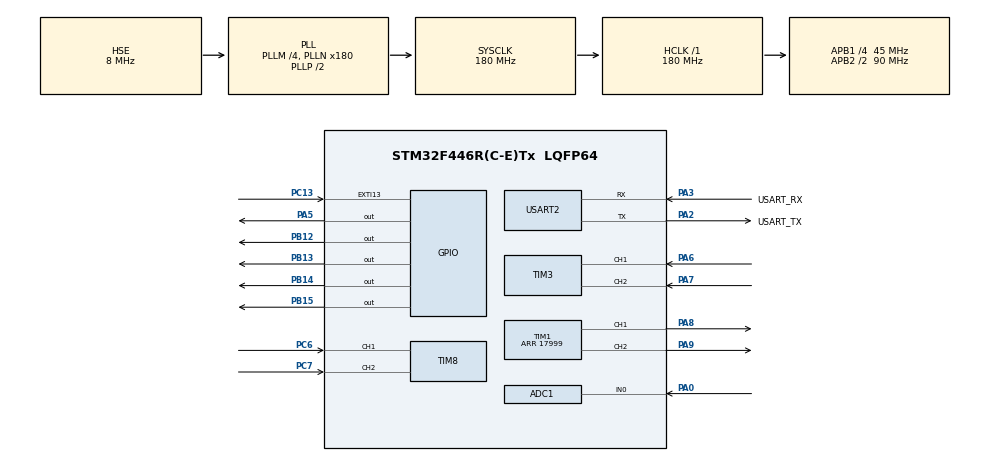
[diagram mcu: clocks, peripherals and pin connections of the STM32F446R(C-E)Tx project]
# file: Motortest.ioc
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ADC1.Channel-0\#ChannelRegularConversion=ADC_CHANNEL_0
ADC1.NbrOfConversionFlag=1
ADC1.Rank-0\#ChannelRegularConversion=1
ADC1.SamplingTime-0\#ChannelRegularConversion=ADC_SAMPLETIME_480CYCLES
ADC1.master=1
Mcu.Family=STM32F4
Mcu.Name=STM32F446R(C-E)Tx
Mcu.Package=LQFP64
NUCLEO-F446RE.BUTTON=1
NUCLEO-F446RE.LD1=true
NVIC.EXTI15_10_IRQn=true\:0\:0\:false\:false\:true\:false\:true\:true
NVIC.PriorityGroup=NVIC_PRIORITYGROUP_0
NVIC.TIM6_DAC_IRQn=true\:0\:0\:false\:false\:true\:true\:true\:true
NVIC.USART2_IRQn=true\:0\:0\:false\:false\:true\:true\:true\:true
PA0-WKUP.Signal=ADCx_IN0
PA13.GPIO_Label=TMS
PA13.Mode=Serial_Wire
PA13.Signal=SYS_JTMS-SWDIO
PA14.GPIO_Label=TCK
PA14.Mode=Serial_Wire
PA14.Signal=SYS_JTCK-SWCLK
PA2.GPIO_Label=USART_TX
PA2.Mode=Asynchronous
PA2.Signal=USART2_TX
PA3.GPIO_Label=USART_RX
PA3.Mode=Asynchronous
PA3.Signal=USART2_RX
PA5.Signal=GPIO_Output
PA6.Signal=S_TIM3_CH1
PA7.Signal=S_TIM3_CH2
PA8.Signal=S_TIM1_CH1
PA9.Signal=S_TIM1_CH2
PB12.GPIO_PuPd=GPIO_PULLDOWN
PB12.Signal=GPIO_Output
PB13.GPIO_PuPd=GPIO_PULLDOWN
PB13.Signal=GPIO_Output
PB14.GPIO_PuPd=GPIO_PULLDOWN
PB14.Signal=GPIO_Output
PB15.GPIO_PuPd=GPIO_PULLDOWN
PB15.Signal=GPIO_Output
PB3.GPIO_Label=SWO
PB3.Signal=SYS_JTDO-SWO
PC13.Signal=GPXTI13
PC14-OSC32_IN.Signal=RCC_OSC32_IN
PC15-OSC32_OUT.Signal=RCC_OSC32_OUT
PC6.Signal=S_TIM8_CH1
PC7.Signal=S_TIM8_CH2
PH0-OSC_IN.Mode=HSE-External-Clock-Source
PH0-OSC_IN.Signal=RCC_OSC_IN
PH1-OSC_OUT.Mode=HSE-External-Clock-Source
PH1-OSC_OUT.Signal=RCC_OSC_OUT
ProjectManager.HeapSize=0x200
ProjectManager.StackSize=0x400
ProjectManager.TargetToolchain=STM32CubeIDE
RCC.AHBFreq_Value=180000000
RCC.APB1CLKDivider=RCC_HCLK_DIV4
RCC.APB1Freq_Value=45000000
RCC.APB1TimFreq_Value=90000000
RCC.APB2CLKDivider=RCC_HCLK_DIV2
RCC.APB2Freq_Value=90000000
RCC.APB2TimFreq_Value=180000000
RCC.CortexFreq_Value=180000000
RCC.FLatency-AdvancedSettings=FLASH_LATENCY_5
RCC.HCLKFreq_Value=180000000
RCC.HSE_VALUE=8000000
RCC.HSI_VALUE=16000000
RCC.PLLM=4
RCC.PLLN=180
RCC.PLLSourceVirtual=RCC_PLLSOURCE_HSE
RCC.SYSCLKFreq_VALUE=180000000
RCC.SYSCLKSource=RCC_SYSCLKSOURCE_PLLCLK
RCC.USBFreq_Value=180000000
RCC.VCOOutputFreq_Value=360000000
SH.ADCx_IN0.0=ADC1_IN0,IN0
SH.S_TIM1_CH1.0=TIM1_CH1,PWM Generation1 CH1
SH.S_TIM1_CH2.0=TIM1_CH2,PWM Generation2 CH2
SH.S_TIM3_CH1.0=TIM3_CH1,Encoder_Interface
SH.S_TIM3_CH2.0=TIM3_CH2,Encoder_Interface
SH.S_TIM8_CH1.0=TIM8_CH1,Encoder_Interface
SH.S_TIM8_CH2.0=TIM8_CH2,Encoder_Interface
TIM1.Channel-PWM\ Generation1\ CH1=TIM_CHANNEL_1
TIM1.Channel-PWM\ Generation2\ CH2=TIM_CHANNEL_2
TIM1.Period=17999
TIM2.Prescaler=89
TIM3.EncoderMode=TIM_ENCODERMODE_TI12
TIM3.IC1Filter=15
TIM3.IC2Filter=15
TIM6.Period=9
TIM6.Prescaler=8999
TIM8.ClockDivision=TIM_CLOCKDIVISION_DIV2
TIM8.EncoderMode=TIM_ENCODERMODE_TI12
TIM8.IC1Filter=15
TIM8.IC2Filter=15
USART2.VirtualMode=VM_ASYNC
VP_NUCLEO-F446RE_VS_BSP_COMMON.Mode=COMMON
VP_TIM2_VS_ClockSourceINT.Mode=Internal
VP_TIM6_VS_ClockSourceINT.Mode=Enable_Timer
board=NUCLEO-F446RE

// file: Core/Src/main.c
/* USER CODE BEGIN Header */
/**
  ******************************************************************************
  * @file           : main.c
  * @brief          : Main program body
  ******************************************************************************
  * @attention
  *
  * Copyright (c) 2026 STMicroelectronics.
  * All rights reserved.
  *
  * This software is licensed under terms that can be found in the LICENSE file
  * in the root directory of this software component.
  * If no LICENSE file comes with this software, it is provided AS-IS.
  *
  ******************************************************************************
  */
/* USER CODE END Header */
#include "main.h"

/* USER CODE BEGIN Includes */
#include "bench.h"

/* USER CODE END Includes */

ADC_HandleTypeDef hadc1;

TIM_HandleTypeDef htim1;
TIM_HandleTypeDef htim2;
TIM_HandleTypeDef htim3;
TIM_HandleTypeDef htim6;
TIM_HandleTypeDef htim8;

UART_HandleTypeDef huart2;

void SystemClock_Config(void);
static void MX_GPIO_Init(void);
static void MX_ADC1_Init(void);
static void MX_TIM1_Init(void);
static void MX_TIM2_Init(void);
static void MX_TIM3_Init(void);
static void MX_TIM6_Init(void);
static void MX_TIM8_Init(void);
static void MX_USART2_UART_Init(void);

int main(void)
{

  /* MCU Configuration--------------------------------------------------------*/

  /* Reset of all peripherals, Initializes the Flash interface and the Systick. */
  HAL_Init();

  /* Configure the system clock */
  SystemClock_Config();

  /* Initialize all configured peripherals */
  MX_GPIO_Init();
  MX_ADC1_Init();
  MX_TIM1_Init();
  MX_TIM2_Init();
  MX_TIM3_Init();
  MX_TIM6_Init();
  MX_TIM8_Init();
  MX_USART2_UART_Init();
  /* USER CODE BEGIN 2 */
    bench_init(

    		   &htim1,    /* PWM        */
               &htim3,    /* encoder L  */
               &htim8,    /* encoder R  */
               &htim2,    /* 1 MHz base */
               &htim6,    /* 1 kHz tick */
               &hadc1,
               &huart2);
    bench_run();          /* never returns */
  /* USER CODE END 2 */

  /* Initialize leds */
  BSP_LED_Init(LED2);

  /* Initialize USER push-button, will be used to trigger an interrupt each time it's pressed.*/
  BSP_PB_Init(BUTTON_USER, BUTTON_MODE_EXTI);

  /* Infinite loop */
  while (1)
  {

  }
}

void SystemClock_Config(void)
{
  RCC_OscInitTypeDef RCC_OscInitStruct = {0};
  RCC_ClkInitTypeDef RCC_ClkInitStruct = {0};

  /** Configure the main internal regulator output voltage
  */
  __HAL_RCC_PWR_CLK_ENABLE();
  __HAL_PWR_VOLTAGESCALING_CONFIG(PWR_REGULATOR_VOLTAGE_SCALE1);

  /** Initializes the RCC Oscillators according to the specified parameters
  * in the RCC_OscInitTypeDef structure.
  */
  RCC_OscInitStruct.OscillatorType = RCC_OSCILLATORTYPE_HSE;
  RCC_OscInitStruct.HSEState = RCC_HSE_BYPASS;
  RCC_OscInitStruct.PLL.PLLState = RCC_PLL_ON;
  RCC_OscInitStruct.PLL.PLLSource = RCC_PLLSOURCE_HSE;
  RCC_OscInitStruct.PLL.PLLM = 4;
  RCC_OscInitStruct.PLL.PLLN = 180;
  RCC_OscInitStruct.PLL.PLLP = RCC_PLLP_DIV2;
  RCC_OscInitStruct.PLL.PLLQ = 2;
  RCC_OscInitStruct.PLL.PLLR = 2;
  if (HAL_RCC_OscConfig(&RCC_OscInitStruct) != HAL_OK)
  {
    Error_Handler();
  }

  /** Activate the Over-Drive mode
  */
  if (HAL_PWREx_EnableOverDrive() != HAL_OK)
  {
    Error_Handler();
  }

  /** Initializes the CPU, AHB and APB buses clocks
  */
  RCC_ClkInitStruct.ClockType = RCC_CLOCKTYPE_HCLK|RCC_CLOCKTYPE_SYSCLK
                              |RCC_CLOCKTYPE_PCLK1|RCC_CLOCKTYPE_PCLK2;
  RCC_ClkInitStruct.SYSCLKSource = RCC_SYSCLKSOURCE_PLLCLK;
  RCC_ClkInitStruct.AHBCLKDivider = RCC_SYSCLK_DIV1;
  RCC_ClkInitStruct.APB1CLKDivider = RCC_HCLK_DIV4;
  RCC_ClkInitStruct.APB2CLKDivider = RCC_HCLK_DIV2;

  if (HAL_RCC_ClockConfig(&RCC_ClkInitStruct, FLASH_LATENCY_5) != HAL_OK)
  {
    Error_Handler();
  }
}

static void MX_ADC1_Init(void)
{

  ADC_ChannelConfTypeDef sConfig = {0};

  /** Configure the global features of the ADC (Clock, Resolution, Data Alignment and number of conversion)
  */
  hadc1.Instance = ADC1;
  hadc1.Init.ClockPrescaler = ADC_CLOCK_SYNC_PCLK_DIV4;
  hadc1.Init.Resolution = ADC_RESOLUTION_12B;
  hadc1.Init.ScanConvMode = DISABLE;
  hadc1.Init.ContinuousConvMode = DISABLE;
  hadc1.Init.DiscontinuousConvMode = DISABLE;
  hadc1.Init.ExternalTrigConvEdge = ADC_EXTERNALTRIGCONVEDGE_NONE;
  hadc1.Init.ExternalTrigConv = ADC_SOFTWARE_START;
  hadc1.Init.DataAlign = ADC_DATAALIGN_RIGHT;
  hadc1.Init.NbrOfConversion = 1;
  hadc1.Init.DMAContinuousRequests = DISABLE;
  hadc1.Init.EOCSelection = ADC_EOC_SINGLE_CONV;
  if (HAL_ADC_Init(&hadc1) != HAL_OK)
  {
    Error_Handler();
  }

  /** Configure for the selected ADC regular channel its corresponding rank in the sequencer and its sample time.
  */
  sConfig.Channel = ADC_CHANNEL_0;
  sConfig.Rank = 1;
  sConfig.SamplingTime = ADC_SAMPLETIME_480CYCLES;
  if (HAL_ADC_ConfigChannel(&hadc1, &sConfig) != HAL_OK)
  {
    Error_Handler();
  }

}

static void MX_TIM1_Init(void)
{

  TIM_MasterConfigTypeDef sMasterConfig = {0};
  TIM_OC_InitTypeDef sConfigOC = {0};
  TIM_BreakDeadTimeConfigTypeDef sBreakDeadTimeConfig = {0};

  htim1.Instance = TIM1;
  htim1.Init.Prescaler = 0;
  htim1.Init.CounterMode = TIM_COUNTERMODE_UP;
  htim1.Init.Period = 17999;
  htim1.Init.ClockDivision = TIM_CLOCKDIVISION_DIV1;
  htim1.Init.RepetitionCounter = 0;
  htim1.Init.AutoReloadPreload = TIM_AUTORELOAD_PRELOAD_DISABLE;
  if (HAL_TIM_PWM_Init(&htim1) != HAL_OK)
  {
    Error_Handler();
  }
  sMasterConfig.MasterOutputTrigger = TIM_TRGO_RESET;
  sMasterConfig.MasterSlaveMode = TIM_MASTERSLAVEMODE_DISABLE;
  if (HAL_TIMEx_MasterConfigSynchronization(&htim1, &sMasterConfig) != HAL_OK)
  {
    Error_Handler();
  }
  sConfigOC.OCMode = TIM_OCMODE_PWM1;
  sConfigOC.Pulse = 0;
  sConfigOC.OCPolarity = TIM_OCPOLARITY_HIGH;
  sConfigOC.OCNPolarity = TIM_OCNPOLARITY_HIGH;
  sConfigOC.OCFastMode = TIM_OCFAST_DISABLE;
  sConfigOC.OCIdleState = TIM_OCIDLESTATE_RESET;
  sConfigOC.OCNIdleState = TIM_OCNIDLESTATE_RESET;
  if (HAL_TIM_PWM_ConfigChannel(&htim1, &sConfigOC, TIM_CHANNEL_1) != HAL_OK)
  {
    Error_Handler();
  }
  if (HAL_TIM_PWM_ConfigChannel(&htim1, &sConfigOC, TIM_CHANNEL_2) != HAL_OK)
  {
    Error_Handler();
  }
  sBreakDeadTimeConfig.OffStateRunMode = TIM_OSSR_DISABLE;
  sBreakDeadTimeConfig.OffStateIDLEMode = TIM_OSSI_DISABLE;
  sBreakDeadTimeConfig.LockLevel = TIM_LOCKLEVEL_OFF;
  sBreakDeadTimeConfig.DeadTime = 0;
  sBreakDeadTimeConfig.BreakState = TIM_BREAK_DISABLE;
  sBreakDeadTimeConfig.BreakPolarity = TIM_BREAKPOLARITY_HIGH;
  sBreakDeadTimeConfig.AutomaticOutput = TIM_AUTOMATICOUTPUT_DISABLE;
  if (HAL_TIMEx_ConfigBreakDeadTime(&htim1, &sBreakDeadTimeConfig) != HAL_OK)
  {
    Error_Handler();
  }
  HAL_TIM_MspPostInit(&htim1);

}

static void MX_TIM2_Init(void)
{

  TIM_ClockConfigTypeDef sClockSourceConfig = {0};
  TIM_MasterConfigTypeDef sMasterConfig = {0};

  htim2.Instance = TIM2;
  htim2.Init.Prescaler = 89;
  htim2.Init.CounterMode = TIM_COUNTERMODE_UP;
  htim2.Init.Period = 4294967295;
  htim2.Init.ClockDivision = TIM_CLOCKDIVISION_DIV1;
  htim2.Init.AutoReloadPreload = TIM_AUTORELOAD_PRELOAD_DISABLE;
  if (HAL_TIM_Base_Init(&htim2) != HAL_OK)
  {
    Error_Handler();
  }
  sClockSourceConfig.ClockSource = TIM_CLOCKSOURCE_INTERNAL;
  if (HAL_TIM_ConfigClockSource(&htim2, &sClockSourceConfig) != HAL_OK)
  {
    Error_Handler();
  }
  sMasterConfig.MasterOutputTrigger = TIM_TRGO_RESET;
  sMasterConfig.MasterSlaveMode = TIM_MASTERSLAVEMODE_DISABLE;
  if (HAL_TIMEx_MasterConfigSynchronization(&htim2, &sMasterConfig) != HAL_OK)
  {
    Error_Handler();
  }

}

static void MX_TIM3_Init(void)
{

  TIM_Encoder_InitTypeDef sConfig = {0};
  TIM_MasterConfigTypeDef sMasterConfig = {0};

  htim3.Instance = TIM3;
  htim3.Init.Prescaler = 0;
  htim3.Init.CounterMode = TIM_COUNTERMODE_UP;
  htim3.Init.Period = 65535;
  htim3.Init.ClockDivision = TIM_CLOCKDIVISION_DIV1;
  htim3.Init.AutoReloadPreload = TIM_AUTORELOAD_PRELOAD_DISABLE;
  sConfig.EncoderMode = TIM_ENCODERMODE_TI12;
  sConfig.IC1Polarity = TIM_ICPOLARITY_RISING;
  sConfig.IC1Selection = TIM_ICSELECTION_DIRECTTI;
  sConfig.IC1Prescaler = TIM_ICPSC_DIV1;
  sConfig.IC1Filter = 15;
  sConfig.IC2Polarity = TIM_ICPOLARITY_RISING;
  sConfig.IC2Selection = TIM_ICSELECTION_DIRECTTI;
  sConfig.IC2Prescaler = TIM_ICPSC_DIV1;
  sConfig.IC2Filter = 15;
  if (HAL_TIM_Encoder_Init(&htim3, &sConfig) != HAL_OK)
  {
    Error_Handler();
  }
  sMasterConfig.MasterOutputTrigger = TIM_TRGO_RESET;
  sMasterConfig.MasterSlaveMode = TIM_MASTERSLAVEMODE_DISABLE;
  if (HAL_TIMEx_MasterConfigSynchronization(&htim3, &sMasterConfig) != HAL_OK)
  {
    Error_Handler();
  }

}

static void MX_TIM6_Init(void)
{

  TIM_MasterConfigTypeDef sMasterConfig = {0};

  htim6.Instance = TIM6;
  htim6.Init.Prescaler = 8999;
  htim6.Init.CounterMode = TIM_COUNTERMODE_UP;
  htim6.Init.Period = 9;
  htim6.Init.AutoReloadPreload = TIM_AUTORELOAD_PRELOAD_DISABLE;
  if (HAL_TIM_Base_Init(&htim6) != HAL_OK)
  {
    Error_Handler();
  }
  sMasterConfig.MasterOutputTrigger = TIM_TRGO_RESET;
  sMasterConfig.MasterSlaveMode = TIM_MASTERSLAVEMODE_DISABLE;
  if (HAL_TIMEx_MasterConfigSynchronization(&htim6, &sMasterConfig) != HAL_OK)
  {
    Error_Handler();
  }

}

static void MX_TIM8_Init(void)
{

  TIM_Encoder_InitTypeDef sConfig = {0};
  TIM_MasterConfigTypeDef sMasterConfig = {0};

  htim8.Instance = TIM8;
  htim8.Init.Prescaler = 0;
  htim8.Init.CounterMode = TIM_COUNTERMODE_UP;
  htim8.Init.Period = 65535;
  htim8.Init.ClockDivision = TIM_CLOCKDIVISION_DIV2;
  htim8.Init.RepetitionCounter = 0;
  htim8.Init.AutoReloadPreload = TIM_AUTORELOAD_PRELOAD_DISABLE;
  sConfig.EncoderMode = TIM_ENCODERMODE_TI12;
  sConfig.IC1Polarity = TIM_ICPOLARITY_RISING;
  sConfig.IC1Selection = TIM_ICSELECTION_DIRECTTI;
  sConfig.IC1Prescaler = TIM_ICPSC_DIV1;
  sConfig.IC1Filter = 15;
  sConfig.IC2Polarity = TIM_ICPOLARITY_RISING;
  sConfig.IC2Selection = TIM_ICSELECTION_DIRECTTI;
  sConfig.IC2Prescaler = TIM_ICPSC_DIV1;
  sConfig.IC2Filter = 15;
  if (HAL_TIM_Encoder_Init(&htim8, &sConfig) != HAL_OK)
  {
    Error_Handler();
  }
  sMasterConfig.MasterOutputTrigger = TIM_TRGO_RESET;
  sMasterConfig.MasterSlaveMode = TIM_MASTERSLAVEMODE_DISABLE;
  if (HAL_TIMEx_MasterConfigSynchronization(&htim8, &sMasterConfig) != HAL_OK)
  {
    Error_Handler();
  }

}

static void MX_USART2_UART_Init(void)
{

  huart2.Instance = USART2;
  huart2.Init.BaudRate = 115200;
  huart2.Init.WordLength = UART_WORDLENGTH_8B;
  huart2.Init.StopBits = UART_STOPBITS_1;
  huart2.Init.Parity = UART_PARITY_NONE;
  huart2.Init.Mode = UART_MODE_TX_RX;
  huart2.Init.HwFlowCtl = UART_HWCONTROL_NONE;
  huart2.Init.OverSampling = UART_OVERSAMPLING_16;
  if (HAL_UART_Init(&huart2) != HAL_OK)
  {
    Error_Handler();
  }

}

static void MX_GPIO_Init(void)
{
  GPIO_InitTypeDef GPIO_InitStruct = {0};

  /* GPIO Ports Clock Enable */
  __HAL_RCC_GPIOC_CLK_ENABLE();
  __HAL_RCC_GPIOH_CLK_ENABLE();
  __HAL_RCC_GPIOA_CLK_ENABLE();
  __HAL_RCC_GPIOB_CLK_ENABLE();

  /*Configure GPIO pin Output Level */
  HAL_GPIO_WritePin(GPIOB, GPIO_PIN_12|GPIO_PIN_13|GPIO_PIN_14|GPIO_PIN_15, GPIO_PIN_RESET);

  /*Configure GPIO pins : PB12 PB13 PB14 PB15 */
  GPIO_InitStruct.Pin = GPIO_PIN_12|GPIO_PIN_13|GPIO_PIN_14|GPIO_PIN_15;
  GPIO_InitStruct.Mode = GPIO_MODE_OUTPUT_PP;
  GPIO_InitStruct.Pull = GPIO_PULLDOWN;
  GPIO_InitStruct.Speed = GPIO_SPEED_FREQ_LOW;
  HAL_GPIO_Init(GPIOB, &GPIO_InitStruct);

}

/* USER CODE BEGIN 4 */
void HAL_TIM_PeriodElapsedCallback(TIM_HandleTypeDef *htim)
{
    if (htim->Instance == TIM6) {
        bench_tick_isr();
    }
}
/* USER CODE END 4 */

void Error_Handler(void)
{
  __disable_irq();
  while (1)
  {
  }
}
